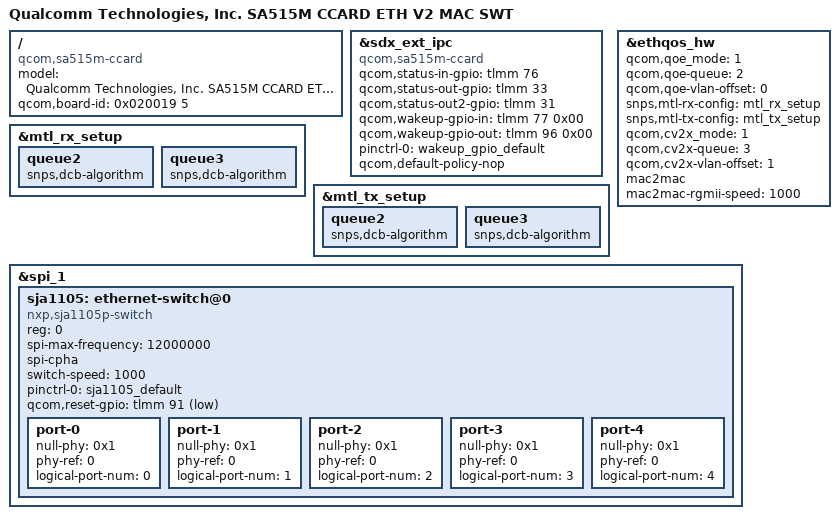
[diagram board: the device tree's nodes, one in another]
/dts-v1/;

#include "sa515m-v2.dtsi"
#include "sa515m-ccard.dtsi"

/ {
	model = "Qualcomm Technologies, Inc. SA515M CCARD ETH V2 MAC SWT";
	compatible = "qcom,sa515m-ccard",
		"qcom,sa515m", "qcom,ccard";
	qcom,board-id = <0x020019 5>;
};

&sdx_ext_ipc {
	compatible = "qcom,sa515m-ccard";
	qcom,status-in-gpio = <&tlmm 76 0x00>;
	qcom,status-out-gpio = <&tlmm 33 0x00>;
	qcom,status-out2-gpio = <&tlmm 31 0x00>;
	qcom,wakeup-gpio-in = <&tlmm 77 0x00>;
	qcom,wakeup-gpio-out = <&tlmm 96 0x00>;
	pinctrl-names = "default";
	pinctrl-0 = <&wakeup_gpio_default>;
	qcom,default-policy-nop;
	status = "okay";
};

&mtl_rx_setup {
	queue2 {
		snps,dcb-algorithm;
		/delete-property/ snps,route-avcp;
	};

	queue3 {
		snps,dcb-algorithm;
	};
};

&mtl_tx_setup {
	queue2 {
		snps,dcb-algorithm;
	};

	queue3 {
		snps,dcb-algorithm;
	};
};

&ethqos_hw {
	qcom,qoe_mode = <1>;
	qcom,qoe-queue = <2>;
	qcom,qoe-vlan-offset = <0>;
	snps,mtl-rx-config = <&mtl_rx_setup>;
	snps,mtl-tx-config = <&mtl_tx_setup>;
	qcom,cv2x_mode = <1>;
	qcom,cv2x-queue = <3>;
	qcom,cv2x-vlan-offset = <1>;
	mac2mac;
	mac2mac-rgmii-speed = <1000>;
};

&spi_1 {
	status = "okay";

	sja1105: ethernet-switch@0{
		compatible = "nxp,sja1105p-switch";
		reg = <0>;
		spi-max-frequency = <12000000>;
		spi-cpha;
		switch-speed = <1000>;
		pinctrl-names = "default";
		pinctrl-0 = <&sja1105_default>;
		qcom,reset-gpio = <&tlmm 91 0x1>;

		port-0 {
			null-phy = <0x1>;
			phy-ref = < 0 >;
			logical-port-num = < 0 >;
		};

		port-1 {
			null-phy = <0x1>;
			phy-ref = < 0 >;
			logical-port-num = < 1 >;
		};

		port-2 {
			null-phy = <0x1>;
			phy-ref = < 0 >;
			logical-port-num = < 2 >;
		};

		port-3 {
			null-phy = <0x1>;
			phy-ref = < 0 >;
			logical-port-num = < 3 >;
		};

		port-4 {
			null-phy = <0x1>;
			phy-ref = < 0 >;
			logical-port-num = < 4 >;
		};
	};
};
